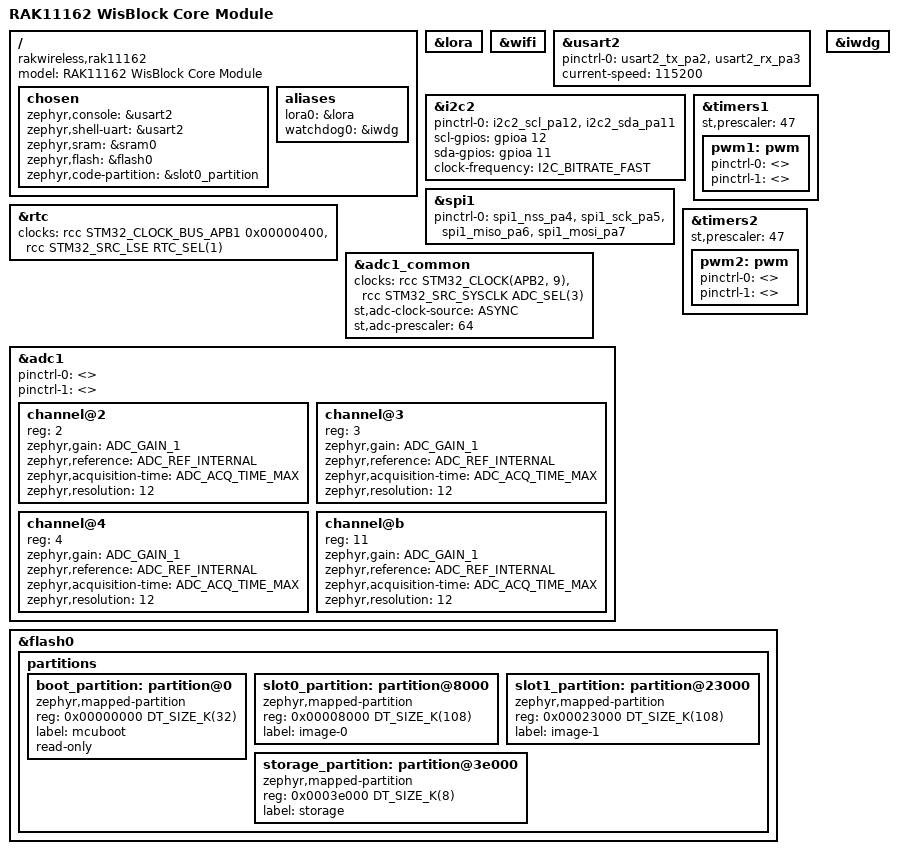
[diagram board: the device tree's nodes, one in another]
/*
 * Copyright (c) 2025 RAKwireless Technology Co., Ltd. <www.rakwireless.com>
 * Sercan Erat <sercanerat@gmail.com>
 * SPDX-License-Identifier: Apache-2.0
 */

/dts-v1/;
#include <rakwireless/rak11160.dtsi>

/ {
	compatible = "rakwireless,rak11162";
	model = "RAK11162 WisBlock Core Module";

	chosen {
		zephyr,console = &usart2;
		zephyr,shell-uart = &usart2;
		zephyr,sram = &sram0;
		zephyr,flash = &flash0;
		zephyr,code-partition = &slot0_partition;
	};

	aliases {
		lora0 = &lora;
		watchdog0 = &iwdg;
	};
};

&lora {
	status = "okay";
};

&wifi {
	status = "okay";
};

&usart2 {
	pinctrl-0 = <&usart2_tx_pa2 &usart2_rx_pa3>;
	pinctrl-names = "default";
	current-speed = <115200>;
	status = "okay";
};

&i2c2 {
	pinctrl-0 = <&i2c2_scl_pa12 &i2c2_sda_pa11>;
	pinctrl-names = "default";
	scl-gpios = <&gpioa 12 GPIO_ACTIVE_HIGH>;
	sda-gpios = <&gpioa 11 GPIO_ACTIVE_HIGH>;
	clock-frequency = <I2C_BITRATE_FAST>;
};

&spi1 {
	pinctrl-0 = <&spi1_nss_pa4 &spi1_sck_pa5
		     &spi1_miso_pa6 &spi1_mosi_pa7>;
	pinctrl-names = "default";
};

&rtc {
	clocks = <&rcc STM32_CLOCK_BUS_APB1 0x00000400>,
		 <&rcc STM32_SRC_LSE RTC_SEL(1)>;
	status = "okay";
};

&adc1_common {
	clocks = <&rcc STM32_CLOCK(APB2, 9)>,
		 <&rcc STM32_SRC_SYSCLK ADC_SEL(3)>;
	clock-names = "adcx", "adc_ker";
	st,adc-clock-source = "ASYNC";
	st,adc-prescaler = <64>;
	status = "okay";
};

/*
 * The connector hands the analog inputs to PWM and to plain GPIO as well, so
 * board.c muxes only the pins an installed module names.
 */
&adc1 {
	#address-cells = <1>;
	#size-cells = <0>;
	pinctrl-0 = <>;
	pinctrl-1 = <>;
	pinctrl-names = "default", "sleep";
	status = "okay";

	channel@2 {
		reg = <2>;
		zephyr,gain = "ADC_GAIN_1";
		zephyr,reference = "ADC_REF_INTERNAL";
		zephyr,acquisition-time = <ADC_ACQ_TIME_MAX>;
		zephyr,resolution = <12>;
	};

	channel@3 {
		reg = <3>;
		zephyr,gain = "ADC_GAIN_1";
		zephyr,reference = "ADC_REF_INTERNAL";
		zephyr,acquisition-time = <ADC_ACQ_TIME_MAX>;
		zephyr,resolution = <12>;
	};

	channel@4 {
		reg = <4>;
		zephyr,gain = "ADC_GAIN_1";
		zephyr,reference = "ADC_REF_INTERNAL";
		zephyr,acquisition-time = <ADC_ACQ_TIME_MAX>;
		zephyr,resolution = <12>;
	};

	channel@b {
		reg = <11>;
		zephyr,gain = "ADC_GAIN_1";
		zephyr,reference = "ADC_REF_INTERNAL";
		zephyr,acquisition-time = <ADC_ACQ_TIME_MAX>;
		zephyr,resolution = <12>;
	};
};

&timers1 {
	st,prescaler = <47>;
	status = "okay";

	pwm1: pwm {
		pinctrl-0 = <>;
		pinctrl-1 = <>;
		pinctrl-names = "default", "sleep";
		status = "okay";
	};
};

&timers2 {
	st,prescaler = <47>;
	status = "okay";

	pwm2: pwm {
		pinctrl-0 = <>;
		pinctrl-1 = <>;
		pinctrl-names = "default", "sleep";
		status = "okay";
	};
};

&iwdg {
	status = "okay";
};

&flash0 {
	partitions {
		ranges;
		#address-cells = <1>;
		#size-cells = <1>;

		boot_partition: partition@0 {
			compatible = "zephyr,mapped-partition";
			reg = <0x00000000 DT_SIZE_K(32)>;
			label = "mcuboot";
			read-only;
		};

		slot0_partition: partition@8000 {
			compatible = "zephyr,mapped-partition";
			reg = <0x00008000 DT_SIZE_K(108)>;
			label = "image-0";
		};

		slot1_partition: partition@23000 {
			compatible = "zephyr,mapped-partition";
			reg = <0x00023000 DT_SIZE_K(108)>;
			label = "image-1";
		};

		storage_partition: partition@3e000 {
			compatible = "zephyr,mapped-partition";
			reg = <0x0003e000 DT_SIZE_K(8)>;
			label = "storage";
		};
	};
};

#include "wisblock.dtsi"
